# MKW20Z4 register map
Vendor: Freescale Semiconductor, Inc.; Series: Kinetis_W; File version: 1.6
CPU: CM0PLUS r0p0, little endian, no MPU, no FPU, VTOR, 2 interrupt priority bits
Registers are 32-bit, read-write, reset 0x0 unless marked. A register's access mark holds for its fields unless they carry their own. Offsets are from the block's base; [hi:lo] are bit positions.

## DCDC — DC to DC Converter
Base 0x4005A000; register names take the prefix DCDC_
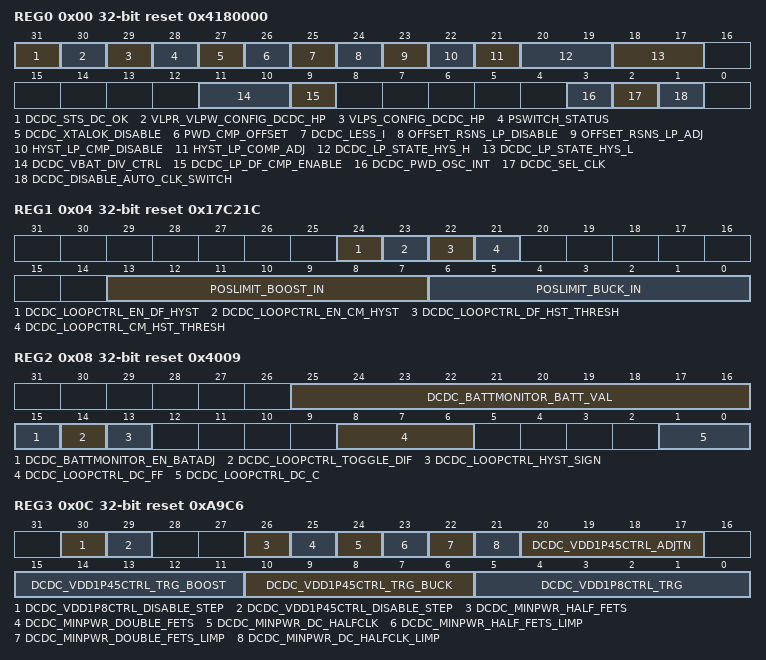
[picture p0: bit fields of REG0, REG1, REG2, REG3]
0x00 REG0 reset 0x4180000 — DCDC REGISTER 0
  [31] DCDC_STS_DC_OK ro — Status register to indicate DCDC lock
  [30] VLPR_VLPW_CONFIG_DCDC_HP — Selects behavior of DCDC in device VLPR and VLPW low power modes
  [29] VLPS_CONFIG_DCDC_HP — Selects behavior of DCDC in device VLPS low power mode
  [28] PSWITCH_STATUS ro — Status register to indicate PSWITCH status
  [27] DCDC_XTALOK_DISABLE — Disable xtalok detection circuit.
  [26] PWD_CMP_OFFSET — Power down output range comparator
  [25] DCDC_LESS_I — Reduce DCDC current. It will save approximately 20uA in RUN.
  [24] OFFSET_RSNS_LP_DISABLE — Disable hysteresis in low power voltage sense.
  [23] OFFSET_RSNS_LP_ADJ — Adjust hysteretic value in low power voltage sense.
  [22] HYST_LP_CMP_DISABLE — Disable hysteresis in low power comparator.
  [21] HYST_LP_COMP_ADJ — Adjust hysteretic value in low power comparator.
  [20:19] DCDC_LP_STATE_HYS_H — Configure the hysteretic upper threshold value in low power mode
    0=Target voltage value + 0 mV; 1=Target voltage value + 25 mV; 2=Target voltage value + 50 mV; 3=Target voltage value + 75 mV
  [18:17] DCDC_LP_STATE_HYS_L — Configure the hysteretic lower threshold value in low power mode
    0=Target voltage value - 0 mV; 1=Target voltage value - 25 mV; 2=Target voltage value - 50 mV; 3=Target voltage value - 75 mV
  [11:10] DCDC_VBAT_DIV_CTRL — Controls VBAT voltage divider
  [9] DCDC_LP_DF_CMP_ENABLE — Enable low power differential comparators, to sense lower supply in pulsed mode
  [3] DCDC_PWD_OSC_INT — Power down internal oscillator. Only set this bit when 32M crystal oscillator is available.
  [2] DCDC_SEL_CLK — Select external clock for DCDC when DCDC_DISABLE_AUTO_CLK_SWITCH is set.
  [1] DCDC_DISABLE_AUTO_CLK_SWITCH — Disable automatic clock switch from internal oscillator to external clock.
0x04 REG1 reset 0x17C21C — DCDC REGISTER 1
  [24] DCDC_LOOPCTRL_EN_DF_HYST — Enable hysteresis in switching converter differential mode analog comparators
  [23] DCDC_LOOPCTRL_EN_CM_HYST — Enable hysteresis in switching converter common mode analog comparators
  [22] DCDC_LOOPCTRL_DF_HST_THRESH — Enable hysteresis in switching converter differential mode analog comparators
  [21] DCDC_LOOPCTRL_CM_HST_THRESH — Enable hysteresis in switching converter common mode analog comparators
  [13:7] POSLIMIT_BOOST_IN — Upper limit duty cycle limit in DC-DC converter
  [6:0] POSLIMIT_BUCK_IN — Upper limit duty cycle limit in DC-DC converter
0x08 REG2 reset 0x4009 — DCDC REGISTER 2
  [25:16] DCDC_BATTMONITOR_BATT_VAL — Software should be configured to place the battery voltage in this register measured with an 8 mV LSB resolution through the ADC
  [15] DCDC_BATTMONITOR_EN_BATADJ — This bit enables the DC-DC to improve efficiency and minimize ripple using the information from the BATT_VAL field
  [14] DCDC_LOOPCTRL_TOGGLE_DIF — Set high to enable supply stepping to change, only after the differential control loop has toggled
  [13] DCDC_LOOPCTRL_HYST_SIGN — Invert the sign of the hysteresis in DC-DC analog comparators. This bit is set when in limp mode.
  [8:6] DCDC_LOOPCTRL_DC_FF — Two complement feed forward step in duty cycle in the switching DC-DC converter
  [1:0] DCDC_LOOPCTRL_DC_C — Ratio of integral control parameter to proportional control parameter in the switching DC-DC converter, it can be used to optimize efficiency and loop response
0x0C REG3 reset 0xA9C6 — DCDC REGISTER 3
  [30] DCDC_VDD1P8CTRL_DISABLE_STEP — Disable stepping for VDD1P8. Must set this bit before enter low power modes.
  [29] DCDC_VDD1P45CTRL_DISABLE_STEP — Disable stepping for VDD1P45. Must set this bit before enter low power modes.
  [26] DCDC_MINPWR_HALF_FETS — Use half switch FET for the continuous mode.
  [25] DCDC_MINPWR_DOUBLE_FETS — Use double switch FET for the continuous mode.
  [24] DCDC_MINPWR_DC_HALFCLK — Set DCDC clock to half frequency for the continuous mode.
  [23] DCDC_MINPWR_HALF_FETS_LIMP — Use half switch FET for the limp mode.
  [22] DCDC_MINPWR_DOUBLE_FETS_LIMP — Use double switch FET for the limp mode.
  [21] DCDC_MINPWR_DC_HALFCLK_LIMP — Set DCDC clock to half frequency for the limp mode.
  [20:17] DCDC_VDD1P45CTRL_ADJTN — Adjust value of duty cycle when switching between VDD1P45 and VDD1P8. The unit is 1/32 or 3.125%.
  [15:11] DCDC_VDD1P45CTRL_TRG_BOOST — Target value of VDD1P45 in bost mode, 25 mV each step from 0x00 to 0x0F
    21=1.8 V; 15=1.65 V; 7=1.45 V; 0=1.275 V
  [10:6] DCDC_VDD1P45CTRL_TRG_BUCK — Target value of VDD1p45 in buck mode, 25 mV each step from 0x00 to 0x0F
    15=1.65 V; 7=1.45 V; 0=1.275 V
  [5:0] DCDC_VDD1P8CTRL_TRG — Target value of VDD1P8, 25 mV each step in two ranges, from 0x00 to 0x11 and 0x20 to 0x3F.
    0=1.65 V; 6=1.8 V; 17=2.075 V; 32=2.8 V; 52=3.3 V; 63=3.575 V
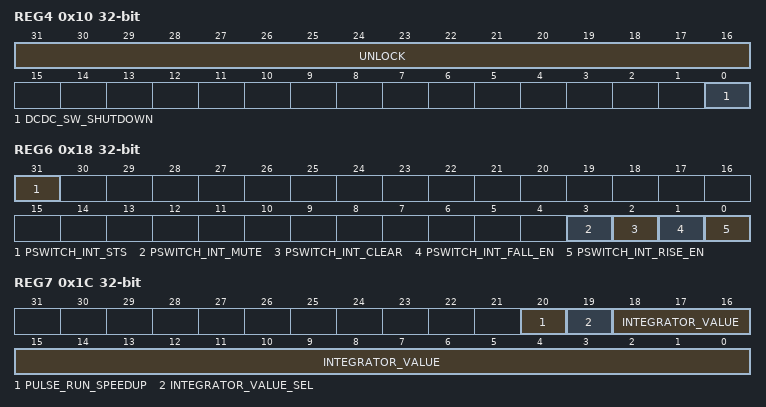
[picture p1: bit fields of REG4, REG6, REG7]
0x10 REG4 — DCDC REGISTER 4
  [31:16] UNLOCK — 0x3E77 KEY-Key needed to unlock HW_POWER_RESET register
  [0] DCDC_SW_SHUTDOWN — Shut down DCDC in buck mode. DCDC can be turned on by pulling PSWITCH to high momentarily (min TBD us).
0x18 REG6 — DCDC REGISTER 6
  [31] PSWITCH_INT_STS ro — PSWITCH edge detection interrupt status
  [3] PSWITCH_INT_MUTE — Mask interrupt to SoC, edge detection result can be read from PSIWTCH_INT_STS.
  [2] PSWITCH_INT_CLEAR — Write 1 to clear interrupt. Set to 0 after clear.
  [1] PSWITCH_INT_FALL_EN — Enable falling edge detect for interrupt.
  [0] PSWITCH_INT_RISE_EN — Enable rising edge detect for interrupt.
0x1C REG7 — DCDC REGISTER 7
  [20] PULSE_RUN_SPEEDUP — Enable pulse run speedup
  [19] INTEGRATOR_VALUE_SEL — Select the integrator value from above register or saved value in hardware.
  [18:0] INTEGRATOR_VALUE — Integrator value which can be loaded in pulsed mode

## Notices in the file
Redistribution and use in source and binary forms, with or without modification,
are permitted provided that the following conditions are met:
o Redistributions of source code must retain the above copyright notice, this list
of conditions and the following disclaimer.
o Redistributions in binary form must reproduce the above copyright notice, this
list of conditions and the following disclaimer in the documentation and/or
other materials provided with the distribution.
o Neither the name of Freescale Semiconductor, Inc. nor the names of its
contributors may be used to endorse or promote products derived from this
software without specific prior written permission.
THIS SOFTWARE IS PROVIDED BY THE COPYRIGHT HOLDERS AND CONTRIBUTORS "AS IS" AND
ANY EXPRESS OR IMPLIED WARRANTIES, INCLUDING, BUT NOT LIMITED TO, THE IMPLIED
WARRANTIES OF MERCHANTABILITY AND FITNESS FOR A PARTICULAR PURPOSE ARE
DISCLAIMED. IN NO EVENT SHALL THE COPYRIGHT HOLDER OR CONTRIBUTORS BE LIABLE FOR
ANY DIRECT, INDIRECT, INCIDENTAL, SPECIAL, EXEMPLARY, OR CONSEQUENTIAL DAMAGES
(INCLUDING, BUT NOT LIMITED TO, PROCUREMENT OF SUBSTITUTE GOODS OR SERVICES;
LOSS OF USE, DATA, OR PROFITS; OR BUSINESS INTERRUPTION) HOWEVER CAUSED AND ON
ANY THEORY OF LIABILITY, WHETHER IN CONTRACT, STRICT LIABILITY, OR TORT
(INCLUDING NEGLIGENCE OR OTHERWISE) ARISING IN ANY WAY OUT OF THE USE OF THIS
SOFTWARE, EVEN IF ADVISED OF THE POSSIBILITY OF SUCH DAMAGE.
